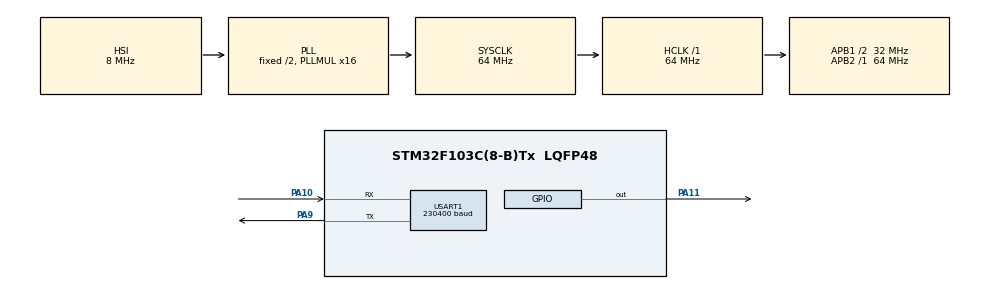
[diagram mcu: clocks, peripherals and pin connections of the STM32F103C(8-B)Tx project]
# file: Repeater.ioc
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Dma.Request0=USART1_RX
Dma.Request1=USART1_TX
Dma.USART1_RX.0.Direction=DMA_PERIPH_TO_MEMORY
Dma.USART1_RX.0.Instance=DMA1_Channel5
Dma.USART1_RX.0.MemDataAlignment=DMA_MDATAALIGN_BYTE
Dma.USART1_RX.0.MemInc=DMA_MINC_ENABLE
Dma.USART1_RX.0.Mode=DMA_NORMAL
Dma.USART1_RX.0.PeriphDataAlignment=DMA_PDATAALIGN_BYTE
Dma.USART1_RX.0.PeriphInc=DMA_PINC_DISABLE
Dma.USART1_RX.0.Priority=DMA_PRIORITY_VERY_HIGH
Dma.USART1_TX.1.Direction=DMA_MEMORY_TO_PERIPH
Dma.USART1_TX.1.Instance=DMA1_Channel4
Dma.USART1_TX.1.MemDataAlignment=DMA_MDATAALIGN_BYTE
Dma.USART1_TX.1.MemInc=DMA_MINC_ENABLE
Dma.USART1_TX.1.Mode=DMA_NORMAL
Dma.USART1_TX.1.PeriphDataAlignment=DMA_PDATAALIGN_BYTE
Dma.USART1_TX.1.PeriphInc=DMA_PINC_DISABLE
Dma.USART1_TX.1.Priority=DMA_PRIORITY_HIGH
Mcu.Family=STM32F1
Mcu.Name=STM32F103C(8-B)Tx
Mcu.Package=LQFP48
NVIC.DMA1_Channel4_IRQn=true\:0\:0\:false\:false\:true\:false
NVIC.DMA1_Channel5_IRQn=true\:0\:0\:false\:false\:true\:false
NVIC.PriorityGroup=NVIC_PRIORITYGROUP_4
NVIC.TIM1_UP_IRQn=true\:0\:0\:false\:false\:true\:true
NVIC.TIM2_IRQn=true\:0\:0\:false\:false\:true\:true
NVIC.USART1_IRQn=true\:0\:0\:false\:false\:true\:true
PA10.Mode=Asynchronous
PA10.Signal=USART1_RX
PA11.Signal=GPIO_Output
PA13.Mode=Serial_Wire
PA13.Signal=SYS_JTMS-SWDIO
PA14.Mode=Serial_Wire
PA14.Signal=SYS_JTCK-SWCLK
PA9.Mode=Asynchronous
PA9.Signal=USART1_TX
ProjectManager.HeapSize=0x200
ProjectManager.StackSize=0x400
ProjectManager.TargetToolchain=MDK-ARM V5
RCC.AHBFreq_Value=64000000
RCC.APB1CLKDivider=RCC_HCLK_DIV2
RCC.APB1Freq_Value=32000000
RCC.APB1TimFreq_Value=64000000
RCC.APB2Freq_Value=64000000
RCC.APB2TimFreq_Value=64000000
RCC.HCLKFreq_Value=64000000
RCC.PLLMUL=RCC_PLL_MUL16
RCC.SYSCLKFreq_VALUE=64000000
RCC.SYSCLKSource=RCC_SYSCLKSOURCE_PLLCLK
RCC.USBFreq_Value=64000000
TIM1.AutoReloadPreload=TIM_AUTORELOAD_PRELOAD_ENABLE
TIM1.Period=65535
TIM1.Prescaler=64
TIM2.Period=35
TIM2.Prescaler=64000
USART1.BaudRate=230400
USART1.VirtualMode=VM_ASYNC
VP_TIM1_VS_ClockSourceINT.Mode=Internal
VP_TIM2_VS_ClockSourceINT.Mode=Internal
board=Repeater

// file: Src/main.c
/**
  ******************************************************************************
  * File Name          : main.c
  * Description        : Main program body
  ******************************************************************************
  ** This notice applies to any and all portions of this file
  * that are not between comment pairs USER CODE BEGIN and
  * USER CODE END. Other portions of this file, whether
  * inserted by the user or by software development tools
  * are owned by their respective copyright owners.
  *
  * COPYRIGHT(c) 2018 STMicroelectronics
  *
  * Redistribution and use in source and binary forms, with or without modification,
  * are permitted provided that the following conditions are met:
  *   1. Redistributions of source code must retain the above copyright notice,
  *      this list of conditions and the following disclaimer.
  *   2. Redistributions in binary form must reproduce the above copyright notice,
  *      this list of conditions and the following disclaimer in the documentation
  *      and/or other materials provided with the distribution.
  *   3. Neither the name of STMicroelectronics nor the names of its contributors
  *      may be used to endorse or promote products derived from this software
  *      without specific prior written permission.
  *
  * THIS SOFTWARE IS PROVIDED BY THE COPYRIGHT HOLDERS AND CONTRIBUTORS "AS IS"
  * AND ANY EXPRESS OR IMPLIED WARRANTIES, INCLUDING, BUT NOT LIMITED TO, THE
  * IMPLIED WARRANTIES OF MERCHANTABILITY AND FITNESS FOR A PARTICULAR PURPOSE ARE
  * DISCLAIMED. IN NO EVENT SHALL THE COPYRIGHT HOLDER OR CONTRIBUTORS BE LIABLE
  * FOR ANY DIRECT, INDIRECT, INCIDENTAL, SPECIAL, EXEMPLARY, OR CONSEQUENTIAL
  * DAMAGES (INCLUDING, BUT NOT LIMITED TO, PROCUREMENT OF SUBSTITUTE GOODS OR
  * SERVICES; LOSS OF USE, DATA, OR PROFITS; OR BUSINESS INTERRUPTION) HOWEVER
  * CAUSED AND ON ANY THEORY OF LIABILITY, WHETHER IN CONTRACT, STRICT LIABILITY,
  * OR TORT (INCLUDING NEGLIGENCE OR OTHERWISE) ARISING IN ANY WAY OUT OF THE USE
  * OF THIS SOFTWARE, EVEN IF ADVISED OF THE POSSIBILITY OF SUCH DAMAGE.
  *
  ******************************************************************************
  */

#include "main.h"
#include "stm32f1xx_hal.h"
#include "dma.h"
#include "tim.h"
#include "usart.h"
#include "gpio.h"

/* USER CODE BEGIN Includes */
#include "Slave.h"

/* USER CODE END Includes */

/* USER CODE BEGIN PV */
/* Private variables ---------------------------------------------------------*/
uint8_t buff;

int temp_TIMOUT_TIM=0;
int temp1=0;
int temp2=0;
uint8_t state_pck;
uint8_t data;

uint8_t audio_buff[Date_Per_100ms];

/* USER CODE END PV */

void SystemClock_Config(void);

/* USER CODE BEGIN PFP */
/* Private function prototypes -----------------------------------------------*/
void HAL_UART_TxCpltCallback(UART_HandleTypeDef *huart);
void HAL_UART_RxCpltCallback(UART_HandleTypeDef *huart);
void HAL_TIM_PeriodElapsedCallback(TIM_HandleTypeDef *htim);
/* USER CODE END PFP */

int main(void)
{

  /* MCU Configuration----------------------------------------------------------*/

  /* Reset of all peripherals, Initializes the Flash interface and the Systick. */
  HAL_Init();

  /* Configure the system clock */
  SystemClock_Config();

  /* Initialize all configured peripherals */
  MX_GPIO_Init();
  MX_DMA_Init();
  MX_USART1_UART_Init();
  MX_TIM2_Init();
  MX_TIM1_Init();

  /* Infinite loop */
  /* USER CODE BEGIN WHILE */
	Slave_Init(2);

	HAL_UART_Receive_IT(&Slave_Uart,&buff,1);

  while (1)
  {
		HAL_Delay(10);
  /* USER CODE END WHILE */

  }

}

/** System Clock Configuration
*/
void SystemClock_Config(void)
{

  RCC_OscInitTypeDef RCC_OscInitStruct;
  RCC_ClkInitTypeDef RCC_ClkInitStruct;

    /**Initializes the CPU, AHB and APB busses clocks
    */
  RCC_OscInitStruct.OscillatorType = RCC_OSCILLATORTYPE_HSI;
  RCC_OscInitStruct.HSIState = RCC_HSI_ON;
  RCC_OscInitStruct.HSICalibrationValue = 16;
  RCC_OscInitStruct.PLL.PLLState = RCC_PLL_ON;
  RCC_OscInitStruct.PLL.PLLSource = RCC_PLLSOURCE_HSI_DIV2;
  RCC_OscInitStruct.PLL.PLLMUL = RCC_PLL_MUL16;
  if (HAL_RCC_OscConfig(&RCC_OscInitStruct) != HAL_OK)
  {
    _Error_Handler(__FILE__, __LINE__);
  }

    /**Initializes the CPU, AHB and APB busses clocks
    */
  RCC_ClkInitStruct.ClockType = RCC_CLOCKTYPE_HCLK|RCC_CLOCKTYPE_SYSCLK
                              |RCC_CLOCKTYPE_PCLK1|RCC_CLOCKTYPE_PCLK2;
  RCC_ClkInitStruct.SYSCLKSource = RCC_SYSCLKSOURCE_PLLCLK;
  RCC_ClkInitStruct.AHBCLKDivider = RCC_SYSCLK_DIV1;
  RCC_ClkInitStruct.APB1CLKDivider = RCC_HCLK_DIV2;
  RCC_ClkInitStruct.APB2CLKDivider = RCC_HCLK_DIV1;

  if (HAL_RCC_ClockConfig(&RCC_ClkInitStruct, FLASH_LATENCY_2) != HAL_OK)
  {
    _Error_Handler(__FILE__, __LINE__);
  }

    /**Configure the Systick interrupt time
    */
  HAL_SYSTICK_Config(HAL_RCC_GetHCLKFreq()/1000);

    /**Configure the Systick
    */
  HAL_SYSTICK_CLKSourceConfig(SYSTICK_CLKSOURCE_HCLK);

  /* SysTick_IRQn interrupt configuration */
  HAL_NVIC_SetPriority(SysTick_IRQn, 0, 0);
}

/* USER CODE BEGIN 4 */

void HAL_UART_RxCpltCallback(UART_HandleTypeDef *huart){
	switch(slave.state){
		case WAITING_PCK:
			state_pck= GetNewData(buff);

			if(state_pck==PCK_With_Me){
				Send_PCK(Normal_conv,0,0,0,0);
				slave.state=SENDING_HELLO;
			}
			else if(state_pck==PCK_REQ_ME){
				//timer start
				HAL_TIM_Base_Stop_IT(&Timeout_Timer);
				HAL_TIM_Base_Start_IT(&Timeout_Timer);
				Timeout_Timer.Instance->CNT=0;

				HAL_UART_Receive_DMA(&Slave_Uart,audio_buff,Date_Per_100ms);
				slave.state=GETTING_AUDIO;
			}
			else{
				HAL_UART_Abort(&Slave_Uart);
				HAL_UART_Receive_IT(&Slave_Uart,&buff,1);
			}
			break;

		case GETTING_AUDIO:

			// timer end
			HAL_TIM_Base_Stop_IT(&Timeout_Timer);
			Timeout_Timer.Instance->CNT=0;

			Send_Audio(audio_buff,Date_Per_100ms);
			slave.state=SENDING_AUDIO;
			break;

		default :
			HAL_UART_Abort(&Slave_Uart);
			HAL_UART_Receive_IT(&Slave_Uart,&buff,1);
	}
}

void HAL_UART_TxCpltCallback(UART_HandleTypeDef *huart){
	HAL_GPIO_WritePin(RS485_GPIO_PORT,RS485_GPIO_PIN,GPIO_PIN_RESET);
	slave.state=WAITING_PCK;
	HAL_UART_Abort(&Slave_Uart);
	HAL_UART_Receive_IT(&Slave_Uart,&buff,1);
}

void HAL_TIM_PeriodElapsedCallback(TIM_HandleTypeDef *htim){
	if(temp_TIMOUT_TIM!=0){
		HAL_TIM_Base_Stop_IT(&Timeout_Timer);
		Timeout_Timer.Instance->CNT=0;

		Send_Audio(audio_buff,Date_Per_100ms);
		slave.state=SENDING_AUDIO;
	}
	else temp_TIMOUT_TIM=1;
}
/* USER CODE END 4 */

void _Error_Handler(char * file, int line)
{
  while(1)
  {
  }
}

/************************ (C) COPYRIGHT STMicroelectronics *****END OF FILE****/
